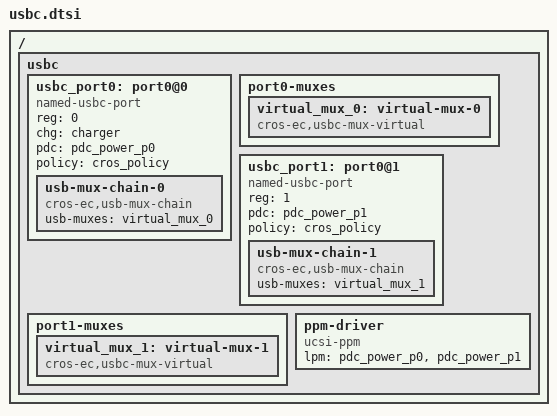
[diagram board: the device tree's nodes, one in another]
/* Copyright 2021 The ChromiumOS Authors
 * Use of this source code is governed by a BSD-style license that can be
 * found in the LICENSE file.
 */

 #include <usbc-policy.dtsi>
 
/ {
	usbc {
		#address-cells = <1>;
		#size-cells = <0>;
		usbc_port0: port0@0 {
			compatible = "named-usbc-port";
			reg = <0>;
			chg = <&charger>;
			pdc = <&pdc_power_p0>;
			policy = <&cros_policy>;
			usb-mux-chain-0 {
				compatible = "cros-ec,usb-mux-chain";
				usb-muxes = <&virtual_mux_0>;
			};
		};

		port0-muxes {
			virtual_mux_0: virtual-mux-0 {
				compatible = "cros-ec,usbc-mux-virtual";
			};
		};

		usbc_port1: port0@1 {
			compatible = "named-usbc-port";
			reg = <1>;
			pdc = <&pdc_power_p1>;
			policy = <&cros_policy>;
			usb-mux-chain-1 {
				compatible = "cros-ec,usb-mux-chain";
				usb-muxes = <&virtual_mux_1>;
			};
		};

		port1-muxes {
			virtual_mux_1: virtual-mux-1 {
				compatible = "cros-ec,usbc-mux-virtual";
			};
		};
		ppm-driver {
			compatible = "ucsi-ppm";
			lpm = <&pdc_power_p0 &pdc_power_p1>;
		};
	};
};
